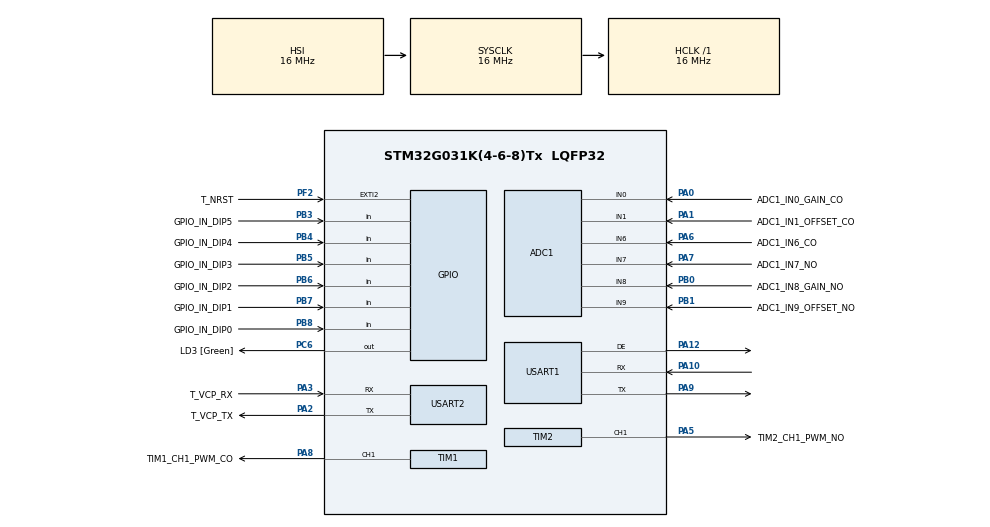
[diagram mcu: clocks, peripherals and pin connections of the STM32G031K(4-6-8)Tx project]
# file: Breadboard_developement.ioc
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ADC1.Channel-1\#ChannelRegularConversion=ADC_CHANNEL_6
ADC1.Channel-2\#ChannelRegularConversion=ADC_CHANNEL_7
ADC1.Channel-3\#ChannelRegularConversion=ADC_CHANNEL_0
ADC1.Channel-4\#ChannelRegularConversion=ADC_CHANNEL_1
ADC1.Channel-5\#ChannelRegularConversion=ADC_CHANNEL_8
ADC1.Channel-6\#ChannelRegularConversion=ADC_CHANNEL_9
ADC1.Channel-8\#ChannelRegularConversion=ADC_CHANNEL_TEMPSENSOR
ADC1.ContinuousConvMode=ENABLE
ADC1.DMAContinuousRequests=DISABLE
ADC1.EOCSelection=ADC_EOC_SEQ_CONV
ADC1.EnableAnalogWatchDog1=false
ADC1.ExternalTrigConv=ADC_SOFTWARE_START
ADC1.NbrOfConversion=7
ADC1.NbrOfConversionFlag=1
ADC1.Overrun=ADC_OVR_DATA_PRESERVED
ADC1.Rank-1\#ChannelRegularConversion=1
ADC1.Rank-2\#ChannelRegularConversion=2
ADC1.Rank-3\#ChannelRegularConversion=3
ADC1.Rank-4\#ChannelRegularConversion=4
ADC1.Rank-5\#ChannelRegularConversion=5
ADC1.Rank-6\#ChannelRegularConversion=6
ADC1.Rank-8\#ChannelRegularConversion=7
ADC1.SamplingTime-1\#ChannelRegularConversion=ADC_SAMPLINGTIME_COMMON_1
ADC1.SamplingTime-2\#ChannelRegularConversion=ADC_SAMPLINGTIME_COMMON_1
ADC1.SamplingTime-3\#ChannelRegularConversion=ADC_SAMPLINGTIME_COMMON_1
ADC1.SamplingTime-4\#ChannelRegularConversion=ADC_SAMPLINGTIME_COMMON_1
ADC1.SamplingTime-5\#ChannelRegularConversion=ADC_SAMPLINGTIME_COMMON_1
ADC1.SamplingTime-6\#ChannelRegularConversion=ADC_SAMPLINGTIME_COMMON_1
ADC1.SamplingTime-8\#ChannelRegularConversion=ADC_SAMPLINGTIME_COMMON_1
ADC1.SamplingTimeCommon1=ADC_SAMPLETIME_160CYCLES_5
ADC1.SamplingTimeCommon2=ADC_SAMPLETIME_160CYCLES_5
ADC1.SelectedChannel=ADC_CHANNEL_0|ADC_CHANNEL_1|ADC_CHANNEL_6|ADC_CHANNEL_7|ADC_CHANNEL_TEMPSENSOR|ADC_CHANNEL_8|ADC_CHANNEL_9
ADC1.master=1
Dma.ADC1.1.Direction=DMA_PERIPH_TO_MEMORY
Dma.ADC1.1.EventEnable=DISABLE
Dma.ADC1.1.Instance=DMA1_Channel1
Dma.ADC1.1.MemDataAlignment=DMA_MDATAALIGN_WORD
Dma.ADC1.1.MemInc=DMA_MINC_ENABLE
Dma.ADC1.1.Mode=DMA_CIRCULAR
Dma.ADC1.1.PeriphDataAlignment=DMA_PDATAALIGN_WORD
Dma.ADC1.1.PeriphInc=DMA_PINC_DISABLE
Dma.ADC1.1.Polarity=HAL_DMAMUX_REQ_GEN_RISING
Dma.ADC1.1.Priority=DMA_PRIORITY_LOW
Dma.ADC1.1.RequestNumber=1
Dma.ADC1.1.SignalID=NONE
Dma.ADC1.1.SyncEnable=DISABLE
Dma.ADC1.1.SyncPolarity=HAL_DMAMUX_SYNC_NO_EVENT
Dma.ADC1.1.SyncRequestNumber=1
Dma.ADC1.1.SyncSignalID=NONE
Dma.Request0=TIM1_CH1
Dma.Request1=ADC1
Dma.Request2=TIM2_CH1
Dma.TIM1_CH1.0.Direction=DMA_MEMORY_TO_PERIPH
Dma.TIM1_CH1.0.EventEnable=DISABLE
Dma.TIM1_CH1.0.Instance=DMA1_Channel2
Dma.TIM1_CH1.0.MemDataAlignment=DMA_MDATAALIGN_HALFWORD
Dma.TIM1_CH1.0.MemInc=DMA_MINC_ENABLE
Dma.TIM1_CH1.0.Mode=DMA_NORMAL
Dma.TIM1_CH1.0.PeriphDataAlignment=DMA_PDATAALIGN_HALFWORD
Dma.TIM1_CH1.0.PeriphInc=DMA_PINC_DISABLE
Dma.TIM1_CH1.0.Polarity=HAL_DMAMUX_REQ_GEN_RISING
Dma.TIM1_CH1.0.Priority=DMA_PRIORITY_LOW
Dma.TIM1_CH1.0.RequestNumber=1
Dma.TIM1_CH1.0.SignalID=NONE
Dma.TIM1_CH1.0.SyncEnable=DISABLE
Dma.TIM1_CH1.0.SyncPolarity=HAL_DMAMUX_SYNC_NO_EVENT
Dma.TIM1_CH1.0.SyncRequestNumber=1
Dma.TIM1_CH1.0.SyncSignalID=NONE
Dma.TIM2_CH1.2.Direction=DMA_MEMORY_TO_PERIPH
Dma.TIM2_CH1.2.EventEnable=DISABLE
Dma.TIM2_CH1.2.Instance=DMA1_Channel3
Dma.TIM2_CH1.2.MemDataAlignment=DMA_MDATAALIGN_HALFWORD
Dma.TIM2_CH1.2.MemInc=DMA_MINC_ENABLE
Dma.TIM2_CH1.2.Mode=DMA_NORMAL
Dma.TIM2_CH1.2.PeriphDataAlignment=DMA_PDATAALIGN_HALFWORD
Dma.TIM2_CH1.2.PeriphInc=DMA_PINC_DISABLE
Dma.TIM2_CH1.2.Polarity=HAL_DMAMUX_REQ_GEN_RISING
Dma.TIM2_CH1.2.Priority=DMA_PRIORITY_LOW
Dma.TIM2_CH1.2.RequestNumber=1
Dma.TIM2_CH1.2.SignalID=NONE
Dma.TIM2_CH1.2.SyncEnable=DISABLE
Dma.TIM2_CH1.2.SyncPolarity=HAL_DMAMUX_SYNC_NO_EVENT
Dma.TIM2_CH1.2.SyncRequestNumber=1
Dma.TIM2_CH1.2.SyncSignalID=NONE
Mcu.Family=STM32G0
Mcu.Name=STM32G031K(4-6-8)Tx
Mcu.Package=LQFP32
NVIC.DMA1_Channel1_IRQn=true\:0\:0\:false\:false\:true\:false\:true\:true
NVIC.DMA1_Channel2_3_IRQn=true\:0\:0\:false\:false\:true\:false\:true\:true
NVIC.USART1_IRQn=true\:0\:0\:false\:false\:true\:true\:true\:true
PA0.GPIO_Label=ADC1_IN0_GAIN_CO
PA0.Mode=IN0
PA0.Signal=ADC1_IN0
PA1.GPIO_Label=ADC1_IN1_OFFSET_CO
PA1.Mode=IN1
PA1.Signal=ADC1_IN1
PA10.Mode=Asynchronous
PA10.Signal=USART1_RX
PA12\ [PA10].Mode=Hardware Flow Control (RS485)
PA12\ [PA10].Signal=USART1_DE
PA13.GPIO_Label=T_JTMS
PA13.Mode=Serial_Wire
PA13.Signal=SYS_SWDIO
PA14-BOOT0.GPIO_Label=T_JTCK
PA14-BOOT0.Mode=Serial_Wire
PA14-BOOT0.Signal=SYS_SWCLK
PA2.GPIO_Label=T_VCP_TX
PA2.GPIO_PuPd=GPIO_PULLUP
PA2.Mode=Asynchronous
PA2.Signal=USART2_TX
PA3.GPIO_Label=T_VCP_RX
PA3.GPIO_PuPd=GPIO_PULLUP
PA3.Mode=Asynchronous
PA3.Signal=USART2_RX
PA5.GPIO_Label=TIM2_CH1_PWM_NO
PA5.Signal=S_TIM2_CH1_ETR
PA6.GPIO_Label=ADC1_IN6_CO
PA6.Mode=IN6
PA6.Signal=ADC1_IN6
PA7.GPIO_Label=ADC1_IN7_NO
PA7.Mode=IN7
PA7.Signal=ADC1_IN7
PA8.GPIO_Label=TIM1_CH1_PWM_CO
PA8.Signal=S_TIM1_CH1
PA9.Mode=Asynchronous
PA9.Signal=USART1_TX
PB0.GPIO_Label=ADC1_IN8_GAIN_NO
PB0.Mode=IN8
PB0.Signal=ADC1_IN8
PB1.GPIO_Label=ADC1_IN9_OFFSET_NO
PB1.Mode=IN9
PB1.Signal=ADC1_IN9
PB3.GPIO_Label=GPIO_IN_DIP5
PB3.Signal=GPIO_Input
PB4.GPIO_Label=GPIO_IN_DIP4
PB4.Signal=GPIO_Input
PB5.GPIO_Label=GPIO_IN_DIP3
PB5.Signal=GPIO_Input
PB6.GPIO_Label=GPIO_IN_DIP2
PB6.Signal=GPIO_Input
PB7.GPIO_Label=GPIO_IN_DIP1
PB7.Signal=GPIO_Input
PB8.GPIO_Label=GPIO_IN_DIP0
PB8.Signal=GPIO_Input
PC14-OSC32_IN\ (PC14).Mode=LSE-External-Oscillator
PC14-OSC32_IN\ (PC14).Signal=RCC_OSC32_IN
PC15-OSC32_OUT\ (PC15).Mode=LSE-External-Oscillator
PC15-OSC32_OUT\ (PC15).Signal=RCC_OSC32_OUT
PC6.GPIO_Label=LD3 [Green]
PC6.Signal=GPIO_Output
PF2\ -\ NRST.GPIO_Label=T_NRST
PF2\ -\ NRST.Signal=GPXTI2
ProjectManager.HeapSize=0x200
ProjectManager.StackSize=0x400
ProjectManager.TargetToolchain=STM32CubeIDE
RCC.AHBFreq_Value=16000000
RCC.CortexFreq_Value=16000000
RCC.EXTERNAL_CLOCK_VALUE=12288000
RCC.HCLKFreq_Value=16000000
RCC.HSE_VALUE=8000000
RCC.HSI_VALUE=16000000
RCC.SYSCLKFreq_VALUE=16000000
RCC.VCOOutputFreq_Value=128000000
SH.S_TIM1_CH1.0=TIM1_CH1,PWM Generation1 CH1
SH.S_TIM2_CH1_ETR.0=TIM2_CH1,PWM Generation1 CH1
TIM1.Channel-PWM\ Generation1\ CH1=TIM_CHANNEL_1
TIM1.Period=256-1
TIM1.Prescaler=0
TIM2.Channel-PWM\ Generation1\ CH1=TIM_CHANNEL_1
TIM2.Period=256-1
USART1.VirtualMode-Asynchronous=VM_ASYNC
USART1.VirtualMode-Hardware\ Flow\ Control\ (RS485)=VM_ASYNC
USART2.VirtualMode-Asynchronous=VM_ASYNC
USART2.WordLength=WORDLENGTH_8B
VP_ADC1_TempSens_Input.Mode=IN-TempSens
VP_TIM1_VS_ClockSourceINT.Mode=Internal
VP_TIM2_VS_ClockSourceINT.Mode=Internal
board=NUCLEO-G031K8

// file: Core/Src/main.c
/* USER CODE BEGIN Header */
/**
 ******************************************************************************
 * @file           : main.c
 * @brief          : Main program body
 ******************************************************************************
 * @attention
 *
 * Copyright (c) 2023 STMicroelectronics.
 * All rights reserved.
 *
 * This software is licensed under terms that can be found in the LICENSE file
 * in the root directory of this software component.
 * If no LICENSE file comes with this software, it is provided AS-IS.
 *
 ******************************************************************************
 */
/* USER CODE END Header */
#include "main.h"
#include "adc.h"
#include "dma.h"
#include "tim.h"
#include "usart.h"
#include "gpio.h"

/* USER CODE BEGIN Includes */
#include <stdio.h>
#include <stdbool.h>
#include "mmodbusConfig.h"
#include "mmodbus.h"

/* USER CODE END Includes */

void SystemClock_Config(void);

int main(void)
{

  /* MCU Configuration--------------------------------------------------------*/

  /* Reset of all peripherals, Initializes the Flash interface and the Systick. */
  HAL_Init();

  /* Configure the system clock */
  SystemClock_Config();

  /* Initialize all configured peripherals */
  MX_GPIO_Init();
  MX_DMA_Init();
  MX_USART2_UART_Init();
  MX_ADC1_Init();
  MX_TIM1_Init();
  MX_USART1_UART_Init();
  MX_TIM2_Init();
  /* USER CODE BEGIN 2 */

	uint32_t value_adc_DMA[7]={0,0,0,0,0,0,0}; // [NCO, NO, NO offset, NO gain, CO offset, CO gain, int_Temperature] // #TODO restructure as struct instrad array

	/* testing duty cycle
	uint8_t DutyCycle = 50; // Duty cycle in Percent

	TIM1->CCR1 = TIM1->ARR/(100/DutyCycle); //ARR = 256 (8 bit)
	TIM2->CCR1 = TIM1->ARR/(100/DutyCycle); //ARR = 256 (8 bit)
*/

	HAL_TIM_PWM_Start(&htim1, TIM_CHANNEL_1);
	HAL_TIM_PWM_Start(&htim2, TIM_CHANNEL_1);
	//HAL_ADC_Start_DMA(&hadc1, value_adc_DMA, 7); // done in while loop
	HAL_ADC_Start_DMA(&hadc1, value_adc_DMA, 7);
  /* USER CODE END 2 */

  /* Infinite loop */
	while (1)
	{

    /* USER CODE BEGIN 3 */

		//HAL_UART_Transmit_DMA(&huart2, value_adc_DMA, sizeof(value_adc_DMA) ); // #TODO with dma or from written buffer??

		HAL_ADC_Start_DMA(&hadc1, value_adc_DMA, 7); // #TODO export to internal timer callback (trigger)
		/* 	//uncomment for sensor use
		TIM1->CCR1 = TIM1->ARR*value_adc_DMA[0]/4095; //DMA is 12 Bit		CO sensor
		TIM2->CCR1 = TIM1->ARR*value_adc_DMA[1]/4095; //DMA is 12 Bit		NO sensor value

		 */
		TIM1->CCR1 = TIM1->ARR*value_adc_DMA[2]/4095;

	}
  /* USER CODE END 3 */
}

void SystemClock_Config(void)
{
  RCC_OscInitTypeDef RCC_OscInitStruct = {0};
  RCC_ClkInitTypeDef RCC_ClkInitStruct = {0};

  /** Configure the main internal regulator output voltage
  */
  HAL_PWREx_ControlVoltageScaling(PWR_REGULATOR_VOLTAGE_SCALE1);

  /** Initializes the RCC Oscillators according to the specified parameters
  * in the RCC_OscInitTypeDef structure.
  */
  RCC_OscInitStruct.OscillatorType = RCC_OSCILLATORTYPE_HSI;
  RCC_OscInitStruct.HSIState = RCC_HSI_ON;
  RCC_OscInitStruct.HSIDiv = RCC_HSI_DIV1;
  RCC_OscInitStruct.HSICalibrationValue = RCC_HSICALIBRATION_DEFAULT;
  RCC_OscInitStruct.PLL.PLLState = RCC_PLL_NONE;
  if (HAL_RCC_OscConfig(&RCC_OscInitStruct) != HAL_OK)
  {
    Error_Handler();
  }

  /** Initializes the CPU, AHB and APB buses clocks
  */
  RCC_ClkInitStruct.ClockType = RCC_CLOCKTYPE_HCLK|RCC_CLOCKTYPE_SYSCLK
                              |RCC_CLOCKTYPE_PCLK1;
  RCC_ClkInitStruct.SYSCLKSource = RCC_SYSCLKSOURCE_HSI;
  RCC_ClkInitStruct.AHBCLKDivider = RCC_SYSCLK_DIV1;
  RCC_ClkInitStruct.APB1CLKDivider = RCC_HCLK_DIV1;

  if (HAL_RCC_ClockConfig(&RCC_ClkInitStruct, FLASH_LATENCY_0) != HAL_OK)
  {
    Error_Handler();
  }
}

void Error_Handler(void)
{
	__disable_irq();
	while (1)
	{
	}
}
